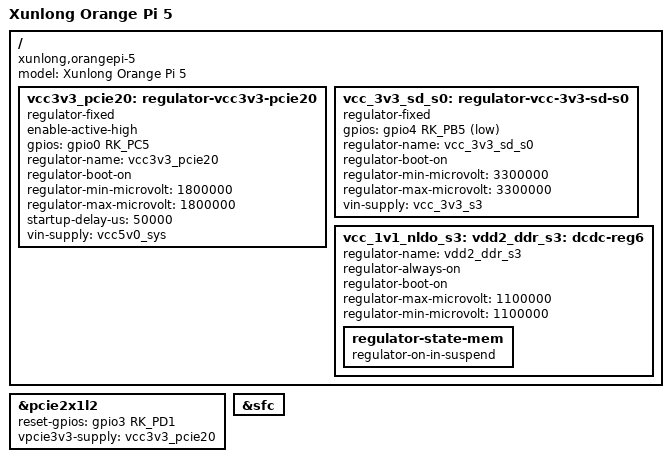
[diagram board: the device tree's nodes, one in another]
// SPDX-License-Identifier: (GPL-2.0+ OR MIT)

/dts-v1/;

#include "rk3588s-orangepi-5.dtsi"

/ {
	model = "Xunlong Orange Pi 5";
	compatible = "xunlong,orangepi-5", "rockchip,rk3588s";

	vcc3v3_pcie20: regulator-vcc3v3-pcie20 {
		compatible = "regulator-fixed";
		enable-active-high;
		gpios = <&gpio0 RK_PC5 GPIO_ACTIVE_HIGH>;
		regulator-name = "vcc3v3_pcie20";
		regulator-boot-on;
		regulator-min-microvolt = <1800000>;
		regulator-max-microvolt = <1800000>;
		startup-delay-us = <50000>;
		vin-supply = <&vcc5v0_sys>;
	};

	vcc_3v3_sd_s0: regulator-vcc-3v3-sd-s0 {
		compatible = "regulator-fixed";
		gpios = <&gpio4 RK_PB5 GPIO_ACTIVE_LOW>;
		regulator-name = "vcc_3v3_sd_s0";
		regulator-boot-on;
		regulator-min-microvolt = <3300000>;
		regulator-max-microvolt = <3300000>;
		vin-supply = <&vcc_3v3_s3>;
	};

	vcc_1v1_nldo_s3: vdd2_ddr_s3: dcdc-reg6 {
		regulator-name = "vdd2_ddr_s3";
		regulator-always-on;
		regulator-boot-on;
		regulator-max-microvolt = <1100000>;
		regulator-min-microvolt = <1100000>;

		regulator-state-mem {
			regulator-on-in-suspend;
		};
	};
};

&pcie2x1l2 {
	reset-gpios = <&gpio3 RK_PD1 GPIO_ACTIVE_HIGH>;
	vpcie3v3-supply = <&vcc3v3_pcie20>;
	status = "okay";
};

&sfc {
	status = "okay";
};
